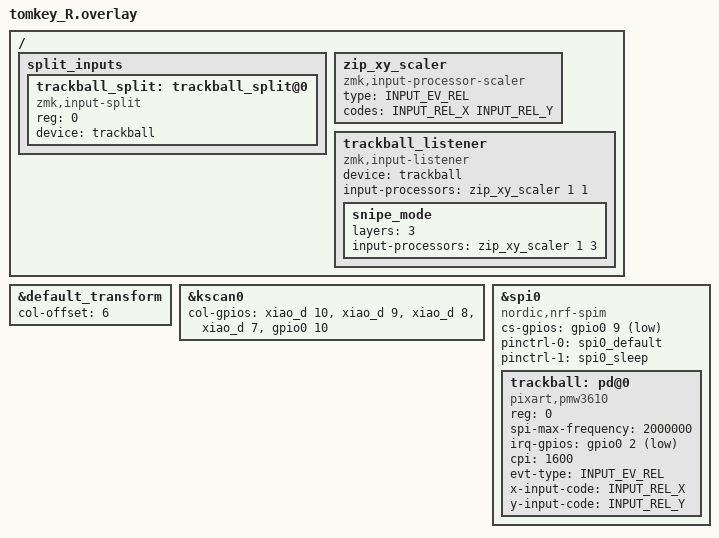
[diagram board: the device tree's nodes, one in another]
#include "tomkey.dtsi"
#include <input/processors.dtsi>
#include <dt-bindings/zmk/input_transform.h>
#include <dt-bindings/zmk/mouse.h>
#include <zephyr/dt-bindings/input/input-event-codes.h>

&default_transform {
    col-offset = <6>;
};

&kscan0 {
    col-gpios
        = <&xiao_d 10 GPIO_ACTIVE_HIGH>
        , <&xiao_d 9 GPIO_ACTIVE_HIGH>
        , <&xiao_d 8 GPIO_ACTIVE_HIGH>
        , <&xiao_d 7 GPIO_ACTIVE_HIGH>
        , <&gpio0 10 GPIO_ACTIVE_HIGH>
        ;
};

&spi0 {
    status = "okay";
    cs-gpios =  <&gpio0 9 GPIO_ACTIVE_LOW>;
    pinctrl-0 = <&spi0_default>;
    pinctrl-1 = <&spi0_sleep>;
    pinctrl-names = "default", "sleep";
    compatible = "nordic,nrf-spim";

    trackball: pd@0 {
        status = "okay";
        compatible = "pixart,pmw3610";
        reg = <0>;
        spi-max-frequency = <2000000>;
        irq-gpios = <&gpio0 2 (GPIO_ACTIVE_LOW | GPIO_PULL_UP)>;
        cpi = <1600>;
        evt-type = <INPUT_EV_REL>;
        x-input-code = <INPUT_REL_X>;
        y-input-code = <INPUT_REL_Y>;
    };
};

/ {
    split_inputs {
        #address-cells = <1>;
        #size-cells = <0>;
        trackball_split: trackball_split@0 {
            compatible = "zmk,input-split";
            reg = <0>;
        };
    };

    /* 標準のスケーラー定義 (ZMK標準仕様準拠) */
    zip_xy_scaler: zip_xy_scaler {
        compatible = "zmk,input-processor-scaler";
        #input-processor-cells = <2>;
        type = <INPUT_EV_REL>;
        codes = <INPUT_REL_X INPUT_REL_Y>;
    };

    /* 標準のリスナー設定 */
    trackball_listener {
        compatible = "zmk,input-listener";
        status = "okay";
        device = <&trackball>;
        
        /* 1. 基本設定 (等倍) */
        input-processors = <&zip_xy_scaler 1 1>;

        /* 2. レイヤー別の上書き設定 (ここが最新仕様の書き方です) */
        snipe_mode {
            layers = <3>;
            input-processors = <&zip_xy_scaler 1 3>; /* 1/3倍速 */
        };
    };
};

&trackball_split {
    device = <&trackball>;
};
